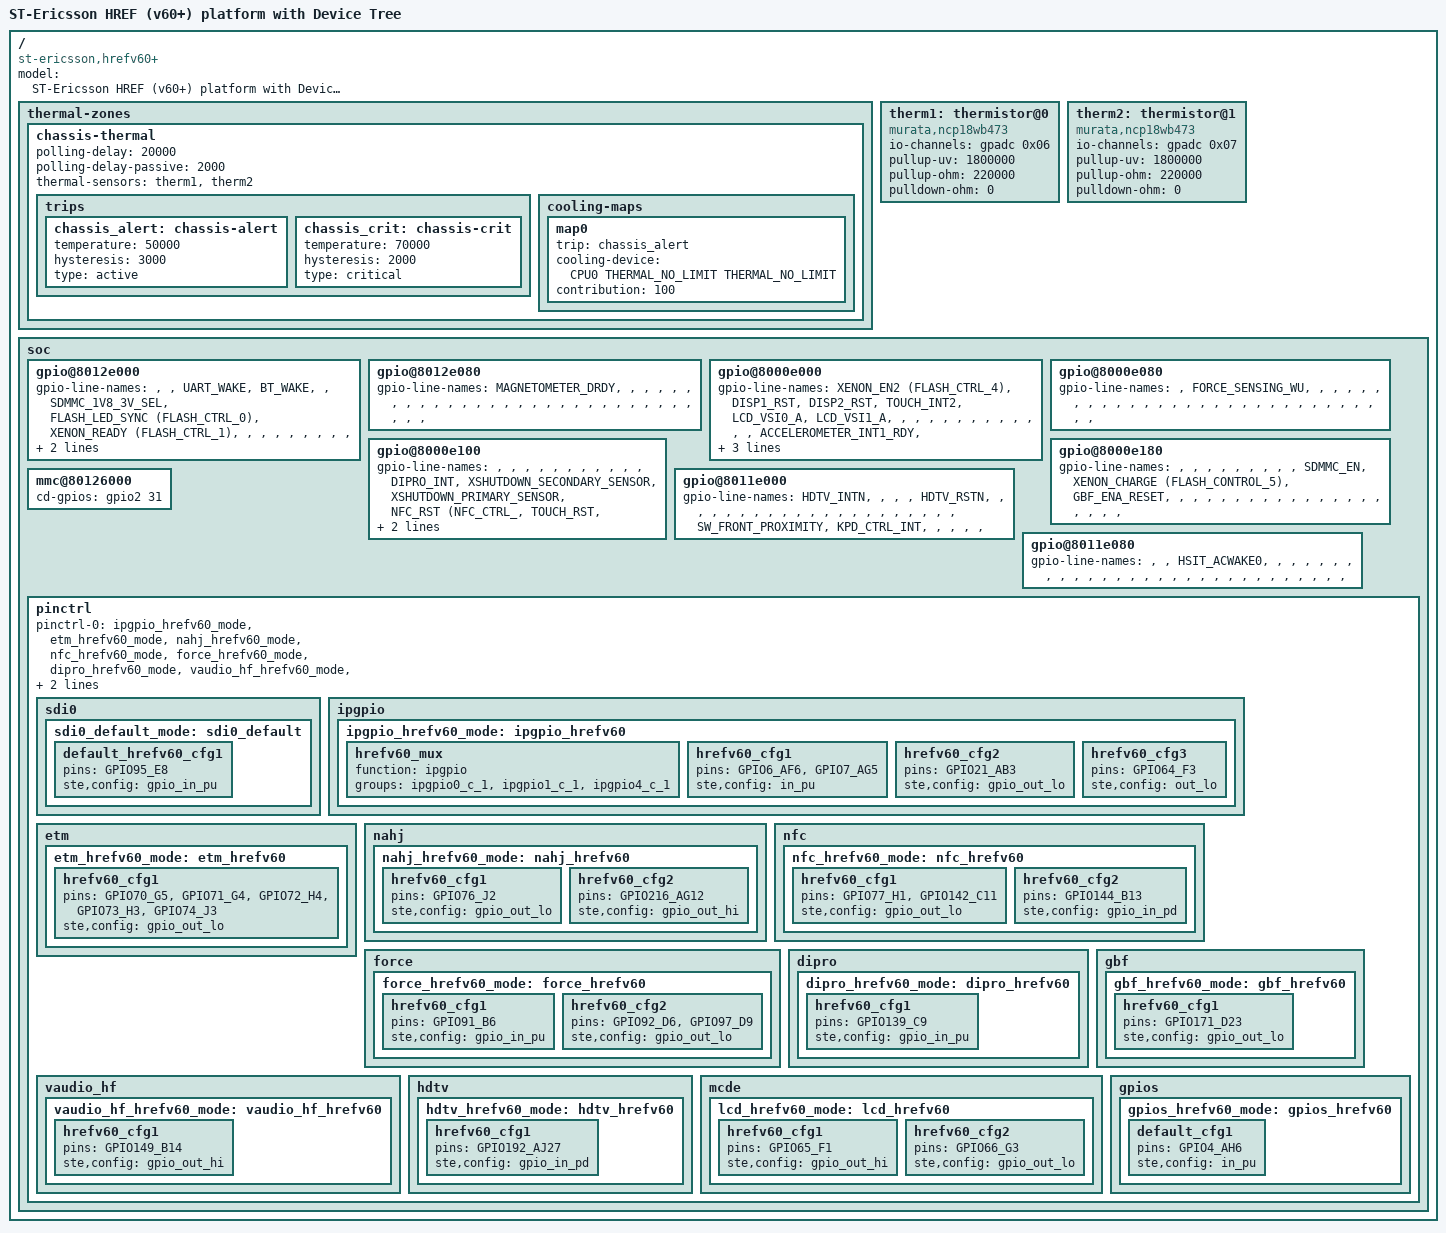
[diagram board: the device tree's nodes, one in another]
#include "ste-href-ab8500.dtsi"
#include "ste-href.dtsi"
/ {
	model = "ST-Ericsson HREF (v60+) platform with Device Tree";
	compatible = "st-ericsson,hrefv60+", "st-ericsson,u8500";
	thermal-zones {
		chassis-thermal {
			polling-delay = <20000>;
			polling-delay-passive = <2000>;
			thermal-sensors = <&therm1>, <&therm2>;
			trips {
				chassis_alert: chassis-alert {
					temperature = <50000>;
					hysteresis = <3000>;
					type = "active";
				};
				chassis_crit: chassis-crit {
					temperature = <70000>;
					hysteresis = <2000>;
					type = "critical";
				};
			};
			cooling-maps {
				map0 {
					trip = <&chassis_alert>;
					cooling-device = <&CPU0 THERMAL_NO_LIMIT THERMAL_NO_LIMIT>;
					contribution = <100>;
				};
			};
		};
	};
	therm1: thermistor@0 {
		compatible = "murata,ncp18wb473";
		io-channels = <&gpadc 0x06>;  
		pullup-uv = <1800000>;
		pullup-ohm = <220000>;
		pulldown-ohm = <0>;
		#thermal-sensor-cells = <0>;
	};
	therm2: thermistor@1 {
		compatible = "murata,ncp18wb473";
		io-channels = <&gpadc 0x07>;  
		pullup-uv = <1800000>;
		pullup-ohm = <220000>;
		pulldown-ohm = <0>;
		#thermal-sensor-cells = <0>;
	};
	soc {
		gpio@8012e000 {
			gpio-line-names =
				     "", "",
				     "UART_WAKE",
				     "BT_WAKE",
				     "",
				     "SDMMC_1V8_3V_SEL",
				     "FLASH_LED_SYNC (FLASH_CTRL_0)",
				     "XENON_READY (FLASH_CTRL_1)",
				     "", "", "", "", "", "", "", "",
				     "", "", "", "",
				     "",
				     "FLASH_LED_EN (FLASH_CTRL_3)",
				     "", "",
				     "", "", "", "", "",
				     "", "",
				     "MAGNETOMETER_INT";
		};
		gpio@8012e080 {
			gpio-line-names =
				     "MAGNETOMETER_DRDY",
				     "", "", "", "", "", "", "",
				     "", "", "", "", "", "", "", "",
				     "", "", "", "", "", "", "", "",
				     "", "", "", "", "", "", "", "";
		};
		gpio@8000e000 {
			gpio-line-names = "XENON_EN2 (FLASH_CTRL_4)",
				     "DISP1_RST",
				     "DISP2_RST",
				     "TOUCH_INT2",
				     "LCD_VSI0_A",
				     "LCD_VSI1_A",
				     "", "", "", "", "", "", "", "",
				     "", "", "", "",
				     "ACCELEROMETER_INT1_RDY",
				     "ACCELEROMETER_INT2",
				     "TOUCH_INT",
				     "WLAN_ENA",
				     "", "", "", "", "",
				     "FORCE_SENSING_INT",
				     "FORCE_SENSING_RESET",
				     "", "",
				     "SDMMC_CD";
		};
		gpio@8000e080 {
			gpio-line-names = "",
				     "FORCE_SENSING_WU",
				     "", "", "", "", "", "",
				     "", "", "", "", "", "", "", "",
				     "", "", "", "", "", "", "", "",
				     "", "", "", "", "", "", "", "";
		};
		gpio@8000e100 {
			gpio-line-names = "", "", "", "", "", "", "", "",
				     "", "", "",
				     "DIPRO_INT",  
				     "XSHUTDOWN_SECONDARY_SENSOR",
				     "XSHUTDOWN_PRIMARY_SENSOR",
				     "NFC_RST (NFC_CTRL_",
				     "TOUCH_RST",
				     "NFC_IRQ (NFC_CTRL_1)",
				     "HAL_SW",
				     "TOUCH_RST2",
				     "", "",
				     "VAUDIO_HF_EN",  
				     "", "", "", "", "", "", "", "", "", "";
		};
		gpio@8000e180 {
			gpio-line-names = "", "", "", "", "", "", "", "",
				     "",
				     "SDMMC_EN",
				     "XENON_CHARGE (FLASH_CONTROL_5)",
				     "GBF_ENA_RESET",
				     "", "", "", "",
				     "", "", "", "", "", "", "", "",
				     "", "", "", "", "", "", "", "";
		};
		gpio@8011e000 {
			gpio-line-names = "HDTV_INTN",
				     "", "", "",
				     "HDTV_RSTN",
				     "", "", "",
				     "",  
				     "", "", "", "", "", "", "",
				     "", "", "", "", "", "", "", "", "",
				     "SW_FRONT_PROXIMITY",  
				     "KPD_CTRL_INT",  
				     "", "", "", "", "";
		};
		gpio@8011e080 {
			gpio-line-names = "", "",
				     "HSIT_ACWAKE0",
				     "", "", "", "", "",
				     "", "", "", "", "", "", "", "",
				     "", "", "", "", "", "", "", "",
				     "", "", "", "", "", "", "", "";
		};
		mmc@80126000 {
			cd-gpios  = <&gpio2 31 GPIO_ACTIVE_HIGH>;  
		};
		pinctrl {
			pinctrl-names = "default";
			pinctrl-0 = <&ipgpio_hrefv60_mode>,
				  <&etm_hrefv60_mode>,
				  <&nahj_hrefv60_mode>,
				  <&nfc_hrefv60_mode>,
				  <&force_hrefv60_mode>,
				  <&dipro_hrefv60_mode>,
				  <&vaudio_hf_hrefv60_mode>,
				  <&gbf_hrefv60_mode>,
				  <&hdtv_hrefv60_mode>,
				  <&gpios_hrefv60_mode>;
			sdi0 {
				sdi0_default_mode: sdi0_default {
					default_hrefv60_cfg1 {
						pins = "GPIO95_E8";
						ste,config = <&gpio_in_pu>;
					};
				};
			};
			ipgpio {
				ipgpio_hrefv60_mode: ipgpio_hrefv60 {
					hrefv60_mux {
						function = "ipgpio";
						groups = "ipgpio0_c_1", "ipgpio1_c_1", "ipgpio4_c_1";
					};
					hrefv60_cfg1 {
						pins = "GPIO6_AF6", "GPIO7_AG5";
						ste,config = <&in_pu>;
					};
					hrefv60_cfg2 {
						pins = "GPIO21_AB3";
						ste,config = <&gpio_out_lo>;
					};
					hrefv60_cfg3 {
						pins = "GPIO64_F3";
						ste,config = <&out_lo>;
					};
				};
			};
			etm {
				etm_hrefv60_mode: etm_hrefv60 {
					hrefv60_cfg1 {
						pins =
						"GPIO70_G5",
						"GPIO71_G4",
						"GPIO72_H4",
						"GPIO73_H3",
						"GPIO74_J3";
						ste,config = <&gpio_out_lo>;
					};
				 };
			};
			nahj {
				nahj_hrefv60_mode: nahj_hrefv60 {
					hrefv60_cfg1 {
						pins = "GPIO76_J2";
						ste,config = <&gpio_out_lo>;
					};
					hrefv60_cfg2 {
						pins = "GPIO216_AG12";
						ste,config = <&gpio_out_hi>;
					};
				 };
			};
			nfc {
				nfc_hrefv60_mode: nfc_hrefv60 {
					hrefv60_cfg1 {
						pins =
						"GPIO77_H1",  
						"GPIO142_C11";  
						ste,config = <&gpio_out_lo>;
					};
					hrefv60_cfg2 {
						pins = "GPIO144_B13";  
						ste,config = <&gpio_in_pd>;
					};
				 };
			};
			force {
				force_hrefv60_mode: force_hrefv60 {
					hrefv60_cfg1 {
						pins = "GPIO91_B6";  
						ste,config = <&gpio_in_pu>;
					};
					hrefv60_cfg2 {
						pins =
						"GPIO92_D6",  
						"GPIO97_D9";  
						ste,config = <&gpio_out_lo>;
					};
				 };
			};
			dipro {
				dipro_hrefv60_mode: dipro_hrefv60 {
					hrefv60_cfg1 {
						pins = "GPIO139_C9";  
						ste,config = <&gpio_in_pu>;
					};
				 };
			};
			vaudio_hf {
				vaudio_hf_hrefv60_mode: vaudio_hf_hrefv60 {
					hrefv60_cfg1 {
						pins = "GPIO149_B14";  
						ste,config = <&gpio_out_hi>;
					};
				 };
			};
			gbf {
				gbf_hrefv60_mode: gbf_hrefv60 {
					hrefv60_cfg1 {
						pins = "GPIO171_D23";  
						ste,config = <&gpio_out_lo>;
					};
				 };
			};
			hdtv {
				hdtv_hrefv60_mode: hdtv_hrefv60 {
					hrefv60_cfg1 {
						pins = "GPIO192_AJ27";
						ste,config = <&gpio_in_pd>;
					};
				 };
			};
			mcde {
				lcd_hrefv60_mode: lcd_hrefv60 {
					hrefv60_cfg1 {
						pins = "GPIO65_F1";
						ste,config = <&gpio_out_hi>;
					};
					hrefv60_cfg2 {
						pins = "GPIO66_G3";
						ste,config = <&gpio_out_lo>;
					};
				};
			};
			gpios {
				gpios_hrefv60_mode: gpios_hrefv60 {
					default_cfg1 {
						pins = "GPIO4_AH6";
						ste,config = <&in_pu>;
					};
				};
			};
		};
	};
};
